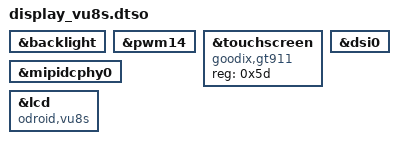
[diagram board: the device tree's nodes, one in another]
/dts-v1/;
/plugin/;

&backlight {
	status = "okay";
};

&pwm14 {
	status = "okay";
};

&touchscreen {
	status = "okay";
	compatible = "goodix,gt911";
	reg = <0x5d>;
};

&mipidcphy0 {
	status = "okay";
};

&dsi0 {
	status = "okay";
};

&lcd {
	compatible = "odroid,vu8s";
};
